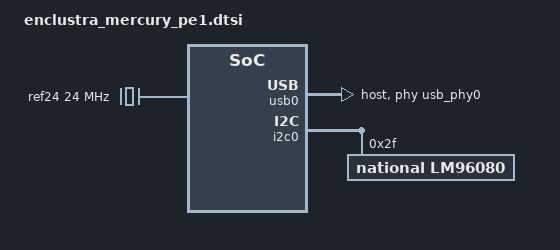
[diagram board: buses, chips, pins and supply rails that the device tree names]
/ {
	usb_phy0: phy0 {
		compatible = "ulpi-phy";
		#phy-cells = <0>;
		reg = <0xe0002000 0x1000>;
		view-port = <0x0170>;
		drv-vbus;
	};
};

&usb0 {
	dr_mode = "host";
	usb-phy = <&usb_phy0>;
};

&sdhci0 {
	disable-wp;
};

&amba {
	ref24: ref24M {
		compatible = "fixed-clock";
		#clock-cells = <0>;
		clock-frequency = <24000000>;
	};
};

&i2c0 {	
	lm96080@2f {
		compatible = "national,lm96080", "lm80";
		reg = <0x2f>;
	};
};
